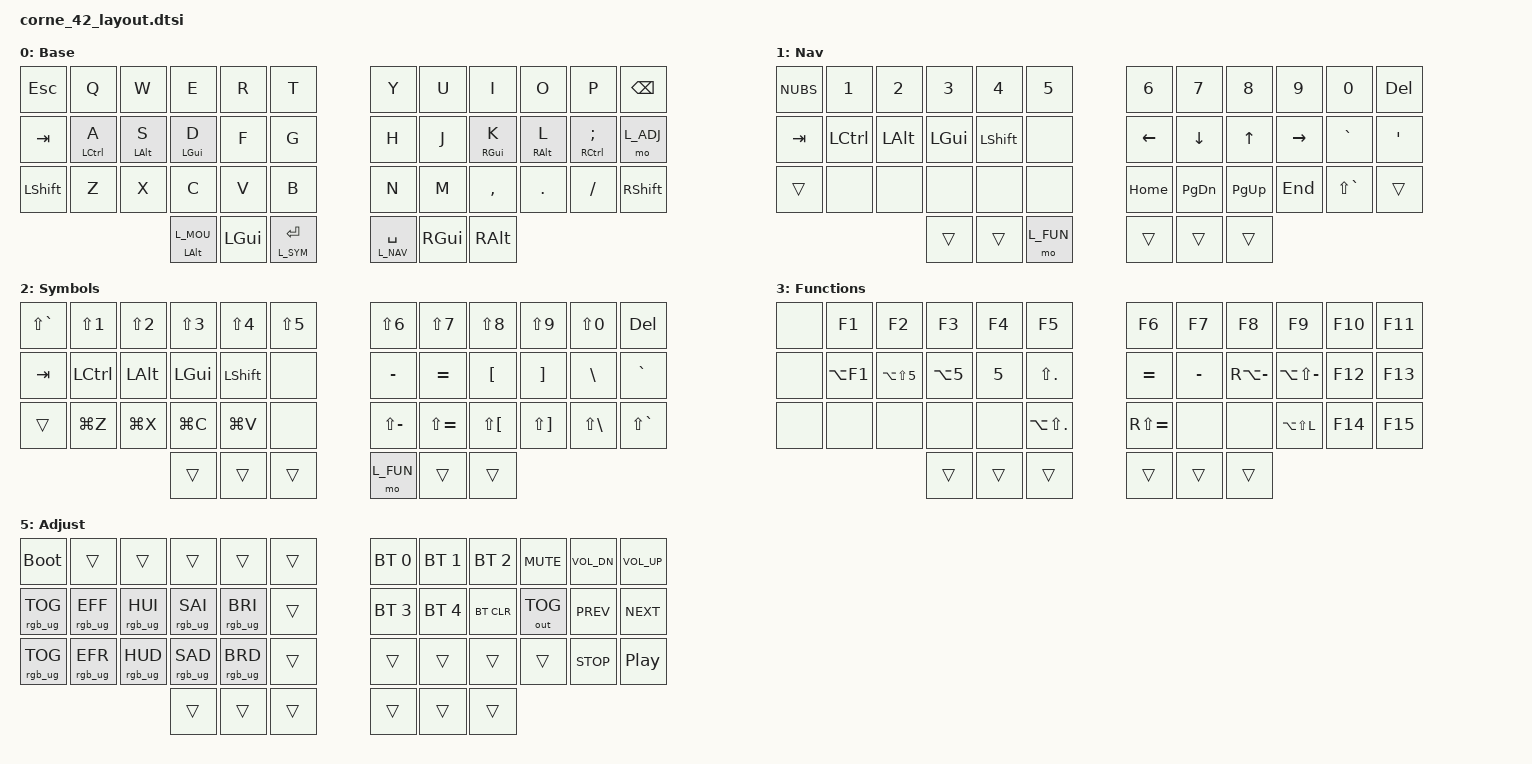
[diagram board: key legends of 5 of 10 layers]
/*
 * Keymap Corne 42 — extraits de corne_vial_layout.dtsi sans macro SOFLE60.
 * Source : vial-qmk/keyboards/crkbd/keymaps/vial/keymap.c
 *
 * Shield ZMK corne : 42 cellules, ordre 3×6+3.
 * Combo J+K+L → Enter : indices 19 20 21 (homerow droite).
 * Couche 4 Mouse : Nuphy Corne uniquement (pas le Sofle).
 */

#include <behaviors.dtsi>
#include <dt-bindings/zmk/bt.h>
#include <dt-bindings/zmk/keys.h>
#include <dt-bindings/zmk/outputs.h>
#include <dt-bindings/zmk/rgb.h>
#ifndef ZMK_POINTING_DEFAULT_MOVE_VAL
#define ZMK_POINTING_DEFAULT_MOVE_VAL 450
#endif
#ifndef ZMK_POINTING_DEFAULT_SCRL_VAL
#define ZMK_POINTING_DEFAULT_SCRL_VAL 35
#endif
/* Pas discret (YUIO). Vitesse two-axis = unités/s ; le pas émis est
 * vitesse × trigger_period / 1000. trigger-period-ms est un uint8 (max 255). */
#ifndef MOUSE_STEP_VAL
#define MOUSE_STEP_VAL 1000
#endif

#include <dt-bindings/zmk/pointing.h>
#include <zephyr/dt-bindings/input/input-event-codes.h>
#include <input/processors.dtsi>

#define L_BASE  0
#define L_NAV   1
#define L_SYM   2
#define L_FUN   3
#define L_MOU   4
#define L_ADJ   5
#define L_SPD05 6
#define L_SPD2  7
#define L_SPD4  8
#define L_SPD6  9

/* Même grille sur Mouse et overlays vitesse : &trans cassait &mkp (sélection).
 * Pas YUIO : le multiplicateur est dans le binding (SV). Le scaler du
 * listener mmv_step ne changeait pas le pas (two-axis ≠ mmv continu). */
#define CORNE_MOUSE_BINDINGS(SV) \
        &tog L_MOU     &mo L_SPD05  &mo L_SPD2   &mo L_SPD4   &mo L_SPD6   &mkp MB4           &mmv_step MOVE_X(-(SV)) &mmv_step MOVE_Y(SV) &mmv_step MOVE_Y(-(SV)) &mmv_step MOVE_X(SV) &kp LG(LS(Z)) &none \
        &none          &none        &mkp RCLK    &mkp MCLK    &mkp LCLK    &mkp MB5           &mmv MOVE_LEFT      &mmv MOVE_DOWN      &mmv MOVE_UP      &mmv MOVE_RIGHT       &tog L_MOU    &mo L_ADJ \
        &none          &kp LG(Z)    &kp LG(X)    &kp LG(C)    &mkp MCLK    &kp LG(V)          &msc SCRL_LEFT      &msc SCRL_DOWN      &msc SCRL_UP      &msc SCRL_RIGHT       &none         &none \
                                    &alt_mou LALT L_MOU &none &none                            &mkp LCLK           &mkp RCLK          &none

/* TAPPING_TERM Corne Vial = 180 ms */
/ {
  behaviors {
    cmt: corne_mod_tap {
      compatible = "zmk,behavior-hold-tap";
      #binding-cells = <2>;
      flavor = "balanced";
      tapping-term-ms = <180>;
      quick-tap-ms = <180>;
      bindings = <&kp>, <&kp>;
    };

    clt: corne_layer_tap {
      compatible = "zmk,behavior-hold-tap";
      #binding-cells = <2>;
      flavor = "balanced";
      tapping-term-ms = <180>;
      quick-tap-ms = <180>;
      bindings = <&mo>, <&kp>;
    };

    /* K56 : hold LAlt, tap = toggle Mouse */
    alt_mou: alt_or_mouse_toggle {
      compatible = "zmk,behavior-hold-tap";
      #binding-cells = <2>;
      flavor = "balanced";
      tapping-term-ms = <180>;
      quick-tap-ms = <180>;
      bindings = <&kp>, <&tog>;
    };

    /* Un rapport HID par appui (pas de rampe / pas de répétition). */
    mmv_step: mouse_move_step {
      compatible = "zmk,behavior-input-two-axis";
      #binding-cells = <1>;
      x-input-code = <INPUT_REL_X>;
      y-input-code = <INPUT_REL_Y>;
      time-to-max-speed-ms = <1>;
      acceleration-exponent = <0>;
      trigger-period-ms = <96>;
    };
  };

  mmv_step_input_listener: mmv_step_input_listener {
    compatible = "zmk,input-listener";
    device = <&mmv_step>;
  };

  combos {
    compatible = "zmk,combos";

    /* EEPROM Corne : J + K + L → Enter (positions Corne 19, 20, 21) */
    combo_jkl_enter {
      timeout-ms = <50>;
      key-positions = <19 20 21>;
      layers = <L_BASE>;
      bindings = <&kp RET>;
    };
  };
};

&mmv {
  time-to-max-speed-ms = <40>;
  acceleration-exponent = <0>;
};

&msc {
  time-to-max-speed-ms = <80>;
  acceleration-exponent = <0>;
};

/* Premier match gagne : ×6 … ×½. Une seule touche vitesse à la fois. */
&mmv_input_listener {
  spd6 {
    layers = <L_SPD6>;
    input-processors = <&zip_xy_scaler 6 1>;
  };
  spd4 {
    layers = <L_SPD4>;
    input-processors = <&zip_xy_scaler 4 1>;
  };
  spd2 {
    layers = <L_SPD2>;
    input-processors = <&zip_xy_scaler 2 1>;
  };
  spd05 {
    layers = <L_SPD05>;
    input-processors = <&zip_xy_scaler 1 2>;
  };
};

/* mmv_step : listener sans scaler — le facteur est dans le keymap (SV). */

&msc_input_listener {
  spd6 {
    layers = <L_SPD6>;
    input-processors = <&zip_scroll_scaler 6 1>;
  };
  spd4 {
    layers = <L_SPD4>;
    input-processors = <&zip_scroll_scaler 4 1>;
  };
  spd2 {
    layers = <L_SPD2>;
    input-processors = <&zip_scroll_scaler 2 1>;
  };
  spd05 {
    layers = <L_SPD05>;
    input-processors = <&zip_scroll_scaler 1 2>;
  };
};

/ {
  keymap {
    compatible = "zmk,keymap";

    BASE {
      display-name = "Base";
      bindings = <
        &kp ESC        &kp Q        &kp W        &kp E        &kp R        &kp T              &kp Y        &kp U        &kp I         &kp O         &kp P            &kp BSPC
        &kp TAB        &cmt LCTRL A &cmt LALT S  &cmt LGUI D  &kp F        &kp G              &kp H        &kp J        &cmt RGUI K   &cmt RALT L   &cmt RCTRL SEMI  &mo L_ADJ
        &kp LSHFT      &kp Z        &kp X        &kp C        &kp V        &kp B              &kp N        &kp M        &kp COMMA     &kp DOT       &kp FSLH         &kp RSHFT
                                    &alt_mou LALT L_MOU &kp LGUI &clt L_SYM RET                  &clt L_NAV SPACE &kp RGUI &kp RALT
      >;
    };

    NAV {
      display-name = "Nav";
      bindings = <
        &kp NUBS       &kp N1       &kp N2       &kp N3       &kp N4       &kp N5             &kp N6       &kp N7       &kp N8        &kp N9        &kp N0           &kp DEL
        &kp TAB        &kp LCTRL    &kp LALT     &kp LGUI     &kp LSHFT    &none              &kp LEFT     &kp DOWN     &kp UP        &kp RIGHT     &kp GRAVE        &kp SQT
        &trans         &none        &none        &none        &none        &none              &kp HOME     &kp PG_DN    &kp PG_UP     &kp END       &kp LS(GRAVE)    &trans
                                    &trans       &trans       &mo L_FUN                       &trans       &trans       &trans
      >;
    };

    SYMBOL {
      display-name = "Symbols";
      bindings = <
        &kp LS(GRAVE)  &kp LS(N1)   &kp LS(N2)   &kp LS(N3)   &kp LS(N4)   &kp LS(N5)         &kp LS(N6)   &kp LS(N7)   &kp LS(N8)    &kp LS(N9)    &kp LS(N0)       &kp DEL
        &kp TAB        &kp LCTRL    &kp LALT     &kp LGUI     &kp LSHFT    &none              &kp MINUS    &kp EQUAL    &kp LBKT      &kp RBKT      &kp BSLH         &kp GRAVE
        &trans         &kp LG(Z)    &kp LG(X)    &kp LG(C)    &kp LG(V)    &none              &kp LS(MINUS) &kp LS(EQUAL) &kp LS(LBKT) &kp LS(RBKT) &kp LS(BSLH)     &kp LS(GRAVE)
                                    &trans       &trans       &trans                          &mo L_FUN    &trans       &trans
      >;
    };

    FUNCTIONS {
      display-name = "Functions";
      bindings = <
        &none          &kp F1       &kp F2       &kp F3       &kp F4       &kp F5             &kp F6       &kp F7       &kp F8        &kp F9        &kp F10          &kp F11
        &none          &kp LA(F1)   &kp LA(LS(N5)) &kp LA(N5) &kp N5       &kp LS(DOT)        &kp EQUAL    &kp MINUS    &kp RA(MINUS) &kp LA(LS(MINUS)) &kp F12      &kp F13
        &none          &none        &none        &none        &none        &kp LA(LS(DOT))    &kp RS(EQUAL) &none       &none         &kp LA(LS(L)) &kp F14          &kp F15
                                    &trans       &trans       &trans                          &trans       &trans       &trans
      >;
    };

    /* Nuphy Corne uniquement. Sofle : Spare dans corne_vial_layout.dtsi. */
    MOUSE {
      display-name = "Mouse";
      bindings = <CORNE_MOUSE_BINDINGS(MOUSE_STEP_VAL)>;
    };

    /* Adjust = Corne L5 (RGB / média / boot) + profils BT */
    ADJUST {
      display-name = "Adjust";
      bindings = <
        &bootloader         &trans            &trans            &trans            &trans            &trans              &bt BT_SEL 0     &bt BT_SEL 1     &bt BT_SEL 2     &kp C_MUTE       &kp C_VOL_DN     &kp C_VOL_UP
        &rgb_ug RGB_TOG     &rgb_ug RGB_EFF   &rgb_ug RGB_HUI   &rgb_ug RGB_SAI   &rgb_ug RGB_BRI   &trans              &bt BT_SEL 3     &bt BT_SEL 4     &bt BT_CLR       &out OUT_TOG     &kp C_PREV       &kp C_NEXT
        &rgb_ug RGB_TOG     &rgb_ug RGB_EFR   &rgb_ug RGB_HUD   &rgb_ug RGB_SAD   &rgb_ug RGB_BRD   &trans              &trans           &trans           &trans           &trans           &kp C_STOP       &kp C_PP
                                            &trans            &trans            &trans                                  &trans           &trans           &trans
      >;
    };

    SPD05 {
      display-name = "×½";
      bindings = <CORNE_MOUSE_BINDINGS((MOUSE_STEP_VAL / 2))>;
    };

    SPD2 {
      display-name = "×2";
      bindings = <CORNE_MOUSE_BINDINGS((MOUSE_STEP_VAL * 2))>;
    };

    SPD4 {
      display-name = "×4";
      bindings = <CORNE_MOUSE_BINDINGS((MOUSE_STEP_VAL * 4))>;
    };

    SPD6 {
      display-name = "×6";
      bindings = <CORNE_MOUSE_BINDINGS((MOUSE_STEP_VAL * 6))>;
    };
  };
};
